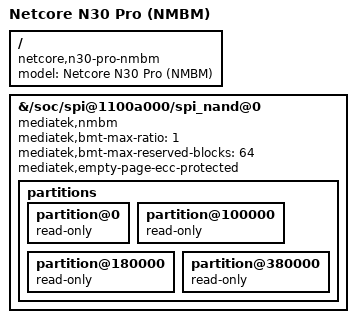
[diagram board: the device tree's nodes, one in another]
// SPDX-License-Identifier: (GPL-2.0-only OR MIT)

#include "mt7981b-netcore-n30-pro.dts"

/ {
	model = "Netcore N30 Pro (NMBM)";
	compatible = "netcore,n30-pro-nmbm", "mediatek,mt7981";
};

/* Reuse an existing NMBM v1 map; never create a replacement map. */
&{/soc/spi@1100a000/spi_nand@0} {
	mediatek,nmbm;
	mediatek,bmt-max-ratio = <1>;
	mediatek,bmt-max-reserved-blocks = <64>;
	mediatek,empty-page-ecc-protected;

	partitions {
		partition@0 {
			read-only;
		};

		partition@100000 {
			read-only;
		};

		partition@180000 {
			read-only;
		};

		partition@380000 {
			read-only;
		};
	};
};
